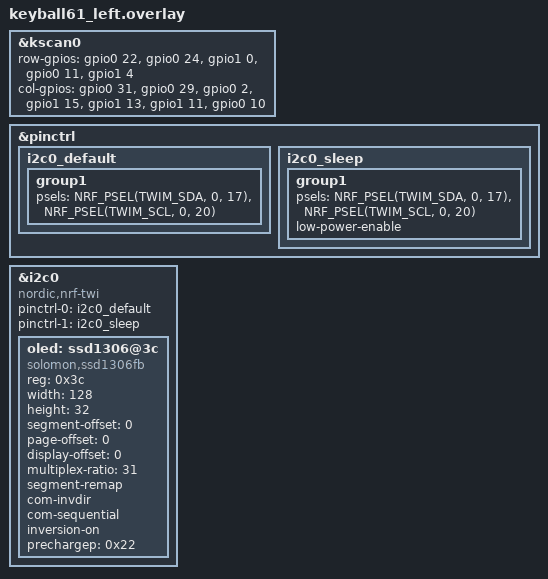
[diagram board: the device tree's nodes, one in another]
/*
 * Copyright (c) 2020 ZMK Contributors
 *
 * SPDX-License-Identifier: MIT
 */

#include "keyball61.dtsi"

&kscan0 {
	row-gpios
	    = <&gpio0 22 (GPIO_ACTIVE_HIGH | GPIO_PULL_DOWN)>  // 実測:P0.22
	    , <&gpio0 24 (GPIO_ACTIVE_HIGH | GPIO_PULL_DOWN)>  // 実測:P0.24
	    , <&gpio1 0  (GPIO_ACTIVE_HIGH | GPIO_PULL_DOWN)>  // 実測:P1.00
	    , <&gpio0 11 (GPIO_ACTIVE_HIGH | GPIO_PULL_DOWN)>  // 実測:P0.11
	    , <&gpio1 4  (GPIO_ACTIVE_HIGH | GPIO_PULL_DOWN)>  // 実測:P1.04
        ;
    col-gpios
        = <&gpio0 31 GPIO_ACTIVE_HIGH> /* ok */
        , <&gpio0 29 GPIO_ACTIVE_HIGH> /* ok */
        , <&gpio0 2 GPIO_ACTIVE_HIGH> /* ok */
		, <&gpio1 15 GPIO_ACTIVE_HIGH> // 4列目 (A0)  ★ここからgpio1
        , <&gpio1 13 GPIO_ACTIVE_HIGH> // 5列目 (D15) ★ここもgpio1
        , <&gpio1 11 GPIO_ACTIVE_HIGH> // 6列目 (D14) ★ここもgpio1
        , <&gpio0 10 GPIO_ACTIVE_HIGH> // 7列目 (D16) ※NFCピン
		;
};

&pinctrl {
    i2c0_default: i2c0_default {
        group1 {
            psels = <NRF_PSEL(TWIM_SDA, 0, 17)>,
                    <NRF_PSEL(TWIM_SCL, 0, 20)>;
        };
    };

    i2c0_sleep: i2c0_sleep {
        group1 {
            psels = <NRF_PSEL(TWIM_SDA, 0, 17)>,
                    <NRF_PSEL(TWIM_SCL, 0, 20)>;
            low-power-enable;
        };
    };
};

&i2c0 {
    status = "okay";
    compatible = "nordic,nrf-twi";
    pinctrl-0 = <&i2c0_default>;
    pinctrl-1 = <&i2c0_sleep>;
    pinctrl-names = "default", "sleep";

    oled: ssd1306@3c {
        compatible = "solomon,ssd1306fb";
        reg = <0x3c>;
        width = <128>;
        height = <32>;
        segment-offset = <0>;
        page-offset = <0>;
        display-offset = <0>;
        multiplex-ratio = <31>;
        segment-remap;
        com-invdir;
        com-sequential;
        inversion-on;
        prechargep = <0x22>;
    };
};
